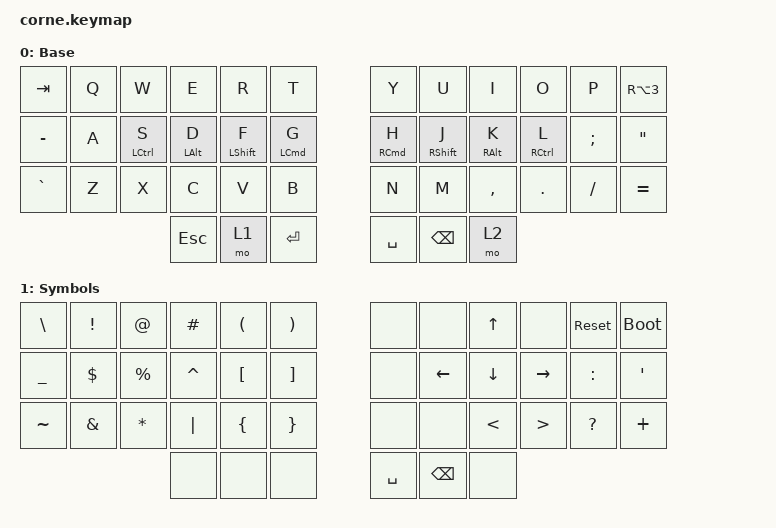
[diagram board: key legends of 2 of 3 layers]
/*
 * Copyright (c) 2020 The ZMK Contributors
 *
 * SPDX-License-Identifier: MIT
 */

#include <behaviors.dtsi>
#include <dt-bindings/zmk/keys.h>
#include <dt-bindings/zmk/bt.h>
#include <dt-bindings/zmk/outputs.h>

/ {

	behaviors {
		hm: homerow_mods {
			compatible = "zmk,behavior-hold-tap";
			#binding-cells = <2>;
			flavor = "balanced";
			require-prior-idle-ms = <150>;
			tapping-term-ms = <280>;
			quick-tap-ms = <175>;
			bindings = <&kp>, <&kp>;
		};
	};

	keymap {
                compatible = "zmk,keymap";

                default_layer {
					display-name = "Base";
// ----------------------------------------------------------------------------
// | TAB |  Q  |  W  |  E  |  R  |  T  |   |  Y  |  U   |  I  |  O  |  P  | # |
// |  -  |  A  |  S  |  D  |  F  |  G  |   |  H  |  J   |  K  |  L  |  ;  | " |
// |  `  |  Z  |  X  |  C  |  V  |  B  |   |  N  |  M   |  ,  |  .  |  /  | = |
//                   | ESC | LY1 | ENT |   | SPC | BSPC | LY2 |
                        bindings = <
   &kp TAB   &kp Q &kp W       &kp E      &kp R        &kp T         &kp Y      &kp U        &kp I      &kp O       &kp P    &kp RA(N3)
   &kp MINUS &kp A &hm LCTRL S &hm LALT D &hm LSHIFT F &hm LCMD G    &hm RCMD H &hm RSHIFT J &hm RALT K &hm RCTRL L &kp SEMI &kp DQT
   &kp GRAVE &kp Z &kp X       &kp C      &kp V        &kp B         &kp N      &kp M        &kp COMMA  &kp DOT     &kp FSLH &kp EQUAL
                               &kp ESC    &mo 1        &kp RET       &kp SPACE  &kp BSPC     &mo 2
                        >;
                };

                layer_one {
					display-name = "Symbols";
// ---------------------------------------------------------------------------
// | \ |  !  |  @  |  £  |  (  |  )  |   |     |      | UP  |    | RESET | BOOT |
// | _ |  $  |  %  |  ^  |  [  |  ]  |   |     |  <-  | DWN | -> |   :   |  '   |
// | ~ |  &  |  *  | "|" |  {  |  }  |   |     |      | <   | >  |   ?   |  +   |
//                 |     |     |     |   | SPC | BSPC |     |
                        bindings = <
   &kp BSLH  &kp EXCL &kp AT    &kp POUND &kp LPAR &kp RPAR    &none   &none    &kp UP   &none      &sys_reset &bootloader
   &kp UNDER &kp DLLR &kp PRCNT &kp CARET &kp LBKT &kp RBKT    &none   &kp LEFT &kp DOWN &kp RIGHT  &kp COLON  &kp SQT
   &kp TILDE &kp AMPS &kp STAR  &kp PIPE  &kp LBRC &kp RBRC    &none   &none    &kp LT   &kp GT &kp QMARK  &kp PLUS
                                &none     &none    &none       &kp SPC &kp BSPC &none
                        >;
                };

                layer_two {
					display-name = "Numbers";
// -----------------------------------------------------------------------------------
// | RESET |  1  |  2  |  3  |      |     |   |  |        |        |        |     |  C_MUTE  |
// | BOOT  |  4  |  5  |  6  |  .   |     |   |  |        |        |        |     | C_VOL_UP |
// | OUT   |  7  |  8  |  9  |  0   |     |   |  | BT_NXT | BT_PRV | BT_CLR |     | C_VOL_DN |
//                     |     | BSPC | SPC |   |  |        |        |
                        bindings = <
   &sys_reset   &kp N1 &kp N2 &kp N3 &none    &none    &none     &none      &none      &none      &none &kp C_MUTE
   &bootloader  &kp N4 &kp N5 &kp N6 &kp DOT  &none    &none     &none      &none      &none      &none &kp C_VOL_UP
   &out OUT_TOG &kp N7 &kp N8 &kp N9 &kp N0   &none    &none     &bt BT_NXT &bt BT_PRV &bt BT_CLR &none &kp C_VOL_DN
   					          &none  &kp BSPC &kp SPC  &none     &none      &none      &none
                        >;
                };
        };
};
